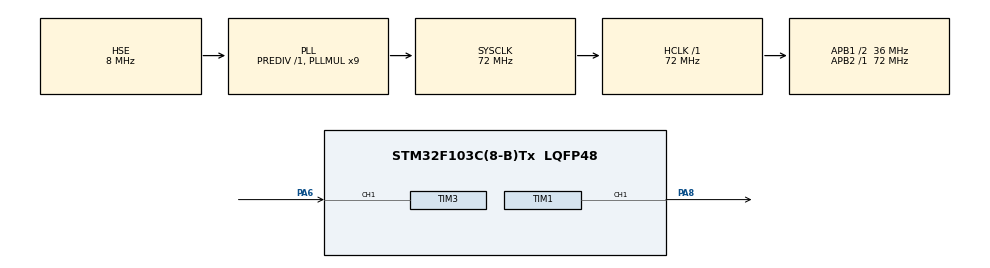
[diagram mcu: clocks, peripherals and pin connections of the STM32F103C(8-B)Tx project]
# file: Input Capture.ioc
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Mcu.Family=STM32F1
Mcu.Name=STM32F103C(8-B)Tx
Mcu.Package=LQFP48
NVIC.PriorityGroup=NVIC_PRIORITYGROUP_4
NVIC.TIM3_IRQn=true\:0\:0\:false\:false\:true\:true\:true
PA13.Mode=Serial_Wire
PA13.Signal=SYS_JTMS-SWDIO
PA14.Mode=Serial_Wire
PA14.Signal=SYS_JTCK-SWCLK
PA6.Signal=S_TIM3_CH1
PA8.Signal=S_TIM1_CH1
PD0-OSC_IN.Mode=HSE-External-Oscillator
PD0-OSC_IN.Signal=RCC_OSC_IN
PD1-OSC_OUT.Mode=HSE-External-Oscillator
PD1-OSC_OUT.Signal=RCC_OSC_OUT
ProjectManager.HeapSize=0x200
ProjectManager.StackSize=0x400
ProjectManager.TargetToolchain=MDK-ARM V5.27
RCC.AHBFreq_Value=72000000
RCC.APB1CLKDivider=RCC_HCLK_DIV2
RCC.APB1Freq_Value=36000000
RCC.APB1TimFreq_Value=72000000
RCC.APB2Freq_Value=72000000
RCC.APB2TimFreq_Value=72000000
RCC.HCLKFreq_Value=72000000
RCC.PLLMUL=RCC_PLL_MUL9
RCC.PLLSourceVirtual=RCC_PLLSOURCE_HSE
RCC.SYSCLKFreq_VALUE=72000000
RCC.SYSCLKSource=RCC_SYSCLKSOURCE_PLLCLK
RCC.USBFreq_Value=72000000
SH.S_TIM1_CH1.0=TIM1_CH1,PWM Generation1 CH1
SH.S_TIM3_CH1.0=TIM3_CH1,Input_Capture1_from_TI1
TIM1.Channel-PWM\ Generation1\ CH1=TIM_CHANNEL_1
TIM1.Period=99
TIM1.Prescaler=719
TIM3.Channel-Input_Capture1_from_TI1=TIM_CHANNEL_1
TIM3.Period=0xffff
TIM3.Prescaler=71
VP_TIM1_VS_ClockSourceINT.Mode=Internal
VP_TIM3_VS_ClockSourceINT.Mode=Internal
board=custom

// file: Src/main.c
#include "main.h"

TIM_HandleTypeDef htim1;
TIM_HandleTypeDef htim3;

/* USER CODE BEGIN PV */
uint32_t value1 = 0;
uint32_t value2 = 0;
uint32_t delta = 0;
uint32_t freq = 0;
uint32_t Is_First_Capture = 0;
/* USER CODE END PV */

void SystemClock_Config(void);
static void MX_GPIO_Init(void);
static void MX_TIM1_Init(void);
static void MX_TIM3_Init(void);

/* USER CODE BEGIN 0 */
void HAL_TIM_IC_CaptureCallback(TIM_HandleTypeDef *htim)
{
	if(htim->Channel == HAL_TIM_ACTIVE_CHANNEL_1)
	{
		if(Is_First_Capture == 0)
		{
			value1 = HAL_TIM_ReadCapturedValue(&htim3,TIM_CHANNEL_1);
			Is_First_Capture = 1;
		}
		else if(Is_First_Capture == 1)
		{
			value2 = HAL_TIM_ReadCapturedValue(&htim3,TIM_CHANNEL_1);
			if( value2 > value1)
			{
				delta = value2 - value1;
			}
			else
			{
				delta = value2 + 0xffff - value1 + 1;
			}
			Is_First_Capture = 0;
			freq = 1000000/delta;
		}
	}
}

/* USER CODE END 0 */

int main(void)
{

  /* MCU Configuration--------------------------------------------------------*/

  /* Reset of all peripherals, Initializes the Flash interface and the Systick. */
  HAL_Init();

  /* Configure the system clock */
  SystemClock_Config();

  /* Initialize all configured peripherals */
  MX_GPIO_Init();
  MX_TIM1_Init();
  MX_TIM3_Init();
  /* USER CODE BEGIN 2 */
	__HAL_TIM_SET_COMPARE(&htim1,TIM_CHANNEL_1,30);
	HAL_TIM_PWM_Start(&htim1,TIM_CHANNEL_1);
	HAL_TIM_IC_Start_IT(&htim3,TIM_CHANNEL_1);
  /* USER CODE END 2 */

  /* Infinite loop */
  while (1)
  {

  }
}

void SystemClock_Config(void)
{
  RCC_OscInitTypeDef RCC_OscInitStruct = {0};
  RCC_ClkInitTypeDef RCC_ClkInitStruct = {0};

  /** Initializes the CPU, AHB and APB busses clocks
  */
  RCC_OscInitStruct.OscillatorType = RCC_OSCILLATORTYPE_HSE;
  RCC_OscInitStruct.HSEState = RCC_HSE_ON;
  RCC_OscInitStruct.HSEPredivValue = RCC_HSE_PREDIV_DIV1;
  RCC_OscInitStruct.HSIState = RCC_HSI_ON;
  RCC_OscInitStruct.PLL.PLLState = RCC_PLL_ON;
  RCC_OscInitStruct.PLL.PLLSource = RCC_PLLSOURCE_HSE;
  RCC_OscInitStruct.PLL.PLLMUL = RCC_PLL_MUL9;
  if (HAL_RCC_OscConfig(&RCC_OscInitStruct) != HAL_OK)
  {
    Error_Handler();
  }
  /** Initializes the CPU, AHB and APB busses clocks
  */
  RCC_ClkInitStruct.ClockType = RCC_CLOCKTYPE_HCLK|RCC_CLOCKTYPE_SYSCLK
                              |RCC_CLOCKTYPE_PCLK1|RCC_CLOCKTYPE_PCLK2;
  RCC_ClkInitStruct.SYSCLKSource = RCC_SYSCLKSOURCE_PLLCLK;
  RCC_ClkInitStruct.AHBCLKDivider = RCC_SYSCLK_DIV1;
  RCC_ClkInitStruct.APB1CLKDivider = RCC_HCLK_DIV2;
  RCC_ClkInitStruct.APB2CLKDivider = RCC_HCLK_DIV1;

  if (HAL_RCC_ClockConfig(&RCC_ClkInitStruct, FLASH_LATENCY_2) != HAL_OK)
  {
    Error_Handler();
  }
}

static void MX_TIM1_Init(void)
{

  TIM_ClockConfigTypeDef sClockSourceConfig = {0};
  TIM_MasterConfigTypeDef sMasterConfig = {0};
  TIM_OC_InitTypeDef sConfigOC = {0};
  TIM_BreakDeadTimeConfigTypeDef sBreakDeadTimeConfig = {0};

  htim1.Instance = TIM1;
  htim1.Init.Prescaler = 719;
  htim1.Init.CounterMode = TIM_COUNTERMODE_UP;
  htim1.Init.Period = 99;
  htim1.Init.ClockDivision = TIM_CLOCKDIVISION_DIV1;
  htim1.Init.RepetitionCounter = 0;
  htim1.Init.AutoReloadPreload = TIM_AUTORELOAD_PRELOAD_DISABLE;
  if (HAL_TIM_Base_Init(&htim1) != HAL_OK)
  {
    Error_Handler();
  }
  sClockSourceConfig.ClockSource = TIM_CLOCKSOURCE_INTERNAL;
  if (HAL_TIM_ConfigClockSource(&htim1, &sClockSourceConfig) != HAL_OK)
  {
    Error_Handler();
  }
  if (HAL_TIM_PWM_Init(&htim1) != HAL_OK)
  {
    Error_Handler();
  }
  sMasterConfig.MasterOutputTrigger = TIM_TRGO_RESET;
  sMasterConfig.MasterSlaveMode = TIM_MASTERSLAVEMODE_DISABLE;
  if (HAL_TIMEx_MasterConfigSynchronization(&htim1, &sMasterConfig) != HAL_OK)
  {
    Error_Handler();
  }
  sConfigOC.OCMode = TIM_OCMODE_PWM1;
  sConfigOC.Pulse = 0;
  sConfigOC.OCPolarity = TIM_OCPOLARITY_HIGH;
  sConfigOC.OCNPolarity = TIM_OCNPOLARITY_HIGH;
  sConfigOC.OCFastMode = TIM_OCFAST_DISABLE;
  sConfigOC.OCIdleState = TIM_OCIDLESTATE_RESET;
  sConfigOC.OCNIdleState = TIM_OCNIDLESTATE_RESET;
  if (HAL_TIM_PWM_ConfigChannel(&htim1, &sConfigOC, TIM_CHANNEL_1) != HAL_OK)
  {
    Error_Handler();
  }
  sBreakDeadTimeConfig.OffStateRunMode = TIM_OSSR_DISABLE;
  sBreakDeadTimeConfig.OffStateIDLEMode = TIM_OSSI_DISABLE;
  sBreakDeadTimeConfig.LockLevel = TIM_LOCKLEVEL_OFF;
  sBreakDeadTimeConfig.DeadTime = 0;
  sBreakDeadTimeConfig.BreakState = TIM_BREAK_DISABLE;
  sBreakDeadTimeConfig.BreakPolarity = TIM_BREAKPOLARITY_HIGH;
  sBreakDeadTimeConfig.AutomaticOutput = TIM_AUTOMATICOUTPUT_DISABLE;
  if (HAL_TIMEx_ConfigBreakDeadTime(&htim1, &sBreakDeadTimeConfig) != HAL_OK)
  {
    Error_Handler();
  }
  HAL_TIM_MspPostInit(&htim1);

}

static void MX_TIM3_Init(void)
{

  TIM_ClockConfigTypeDef sClockSourceConfig = {0};
  TIM_MasterConfigTypeDef sMasterConfig = {0};
  TIM_IC_InitTypeDef sConfigIC = {0};

  htim3.Instance = TIM3;
  htim3.Init.Prescaler = 71;
  htim3.Init.CounterMode = TIM_COUNTERMODE_UP;
  htim3.Init.Period = 0xffff;
  htim3.Init.ClockDivision = TIM_CLOCKDIVISION_DIV1;
  htim3.Init.AutoReloadPreload = TIM_AUTORELOAD_PRELOAD_DISABLE;
  if (HAL_TIM_Base_Init(&htim3) != HAL_OK)
  {
    Error_Handler();
  }
  sClockSourceConfig.ClockSource = TIM_CLOCKSOURCE_INTERNAL;
  if (HAL_TIM_ConfigClockSource(&htim3, &sClockSourceConfig) != HAL_OK)
  {
    Error_Handler();
  }
  if (HAL_TIM_IC_Init(&htim3) != HAL_OK)
  {
    Error_Handler();
  }
  sMasterConfig.MasterOutputTrigger = TIM_TRGO_RESET;
  sMasterConfig.MasterSlaveMode = TIM_MASTERSLAVEMODE_DISABLE;
  if (HAL_TIMEx_MasterConfigSynchronization(&htim3, &sMasterConfig) != HAL_OK)
  {
    Error_Handler();
  }
  sConfigIC.ICPolarity = TIM_INPUTCHANNELPOLARITY_RISING;
  sConfigIC.ICSelection = TIM_ICSELECTION_DIRECTTI;
  sConfigIC.ICPrescaler = TIM_ICPSC_DIV1;
  sConfigIC.ICFilter = 0;
  if (HAL_TIM_IC_ConfigChannel(&htim3, &sConfigIC, TIM_CHANNEL_1) != HAL_OK)
  {
    Error_Handler();
  }

}

static void MX_GPIO_Init(void)
{

  /* GPIO Ports Clock Enable */
  __HAL_RCC_GPIOD_CLK_ENABLE();
  __HAL_RCC_GPIOA_CLK_ENABLE();

}

void Error_Handler(void)
{
}

/************************ (C) COPYRIGHT STMicroelectronics *****END OF FILE****/
